# pag2s register map
Vendor: Infineon Technologies; Series: PAG2S; File version: 1.0
CPU: CM0PLUS r0p1, little endian, MPU, no FPU, VTOR, 2 interrupt priority bits
Registers are 32-bit, read-write, reset 0x0 unless marked. A register's access mark holds for its fields unless they carry their own. Offsets are from the block's base; lines under a group give offsets from that group; [hi:lo] are bit positions; {n}, {i} and the like mark numbered series; 'fields as' and 'values as' point back to an identical list; <NAME> marks a mode.

## Memory map
0x40010000 PERI size 0x10000 — Peripheral Interconnect
0x40020000 HSIOM size 0x4000 — High Speed IO Matrix (HSIOM)
0x40030000 SRSSHV size 0x10000 — System Resources High Voltage Subsystem
0x40040000 GPIO size 0x4000 — GPIO port control/configuration
0x40090000 TCPWM size 0x10000 — Timer/Counter/PWM
0x40100000 CPUSS size 0x1000 — CPU Subsystem
0x40110000 SPCIF size 0x10000 — Flash Control Interface
0x40130000 FAULT size 0x10000 — Fault structures

## Interrupts
0 srss_interrupt_srss (CPUSS) — SRSS interrupts
1 srss_wdt_irq (CPUSS) — WDT Interrupt
2 ioss_interrupt_gpio (CPUSS) — GPIO consolidated interrupt
3 ioss_interrupts_gpio_0 (CPUSS) — GPIO P0
4 ioss_interrupts_gpio_1 (CPUSS) — GPIO P1
5 usbpd_0_interrupt_wakeup (CPUSS) — Ganged USBPD Interrupt
6 cpuss_interrupt_spcif (CPUSS) — SPCIF interrupt
7 cpuss_interrupt_fault_0 (CPUSS) — Fault structure 0 interrupt
8 cpuss_interrupt_fault_1 (CPUSS) — Fault structure 1 interrupt
9 usbpd_0_interrupt (CPUSS) — Synchronous USBPD Interrupts
10 tcpwm_interrupts_0 (CPUSS) — TCPWM counter #0

## HSIOM — High Speed IO Matrix (HSIOM)
Base 0x40020000
{0x0+0x100*i} PRT[{i}] (i=0..1) group — HSIOM port registers
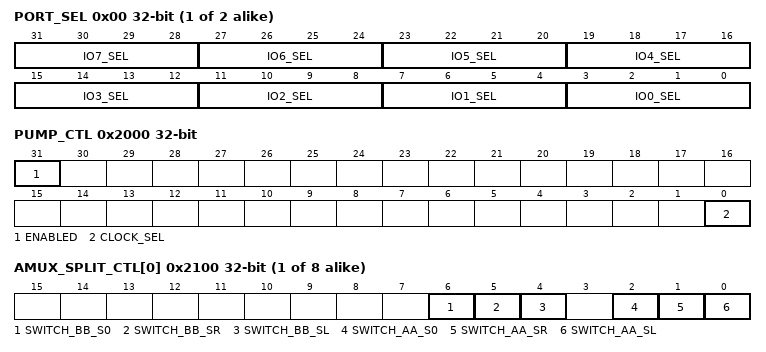
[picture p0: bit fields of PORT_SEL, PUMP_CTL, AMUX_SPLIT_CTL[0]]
  0x00 PORT_SEL — Port selection register
    [4n+3:4n] IO{n}_SEL (n=1..7)
    [3:0] IO0_SEL
      0=GPIO (SW controlled GPIO.); 1=GPIO_DSI (SW controlled 'out', DSI controlled 'oe_n'.); 2=DSI_DSI (DSI controlled 'out' and 'oe_n'.); 3=DSI_GPIO (DSI controlled 'out', SW controlled 'oe_n'.); 4=CSD_SENSE (CSD sense connection (analog mode)); 5=CSD_SHIELD (CSD shield connection (analog mode)); 6=AMUXA (AMUXBUS A connection.); 7=AMUXB (AMUXBUS B connection. This mode is also used for CSD GPIO charging. When CSD GPIO charging is enabled in CSD_CONTROL, 'oe_n' is connected to '!csd_charge' signal (and IO pad is also still connected to AMUXBUS B).); {v}=ACT_{v-8} (Chip specific Active source {v-8} connection.) (v=8..11); 12=LCD_COM (LCD common connection. This mode provides DeepSleep functionality (provided that the LCD block exists, is enabled, and is properly configured).); 13=LCD_SEG (LCD segment connection. This mode provides DeepSleep functionality (provided that the LCD block is enabled and properly configured).); 14=DS_2 (Chip specific DeepSleep source 2 connection.); 15=DS_3 (Chip specific DeepSleep source 3 connection.)
0x2000 PUMP_CTL — Pump control
  [31] ENABLED — Pump enabled: '0': Disabled. '1': Enabled.
  [0] CLOCK_SEL — Clock select: '0': External clock. '1': Internal clock (deprecated).
{0x2100+4i} AMUX_SPLIT_CTL[{i}] (i=0..7) — AMUX splitter cell control
  [6] SWITCH_BB_S0 — T-switch control for AMUXBUSB vssa/ground switch.
  [5] SWITCH_BB_SR — T-switch control for Right AMUXBUSB switch.
  [4] SWITCH_BB_SL — T-switch control for Left AMUXBUSB switch.
  [2] SWITCH_AA_S0 — T-switch control for AMUXBUSA vssa/ground switch: '0': switch open. '1': switch closed.
  [1] SWITCH_AA_SR — T-switch control for Right AMUXBUSA switch: '0': switch open. '1': switch closed.
  [0] SWITCH_AA_SL — T-switch control for Left AMUXBUSA switch: '0': switch open. '1': switch closed.

## Licence text in the file
(c) (2016-2025), Cypress Semiconductor Corporation (an Infineon company) or an affiliate of Cypress Semiconductor Corporation. . SPDX-License-Identifier: Apache-2.0 . Licensed under the Apache License, Version 2.0 (the "License"); you may not use this file except in compliance with the License. You may obtain a copy of the License at http://www.apache.org/licenses/LICENSE-2.0 . Unless required by applicable law or agreed to in writing, software distributed under the License is distributed on an "AS IS" BASIS, WITHOUT WARRANTIES OR CONDITIONS OF ANY KIND, either express or implied. See the License for the specific language governing permissions and limitations under the License.
